VERSION ""

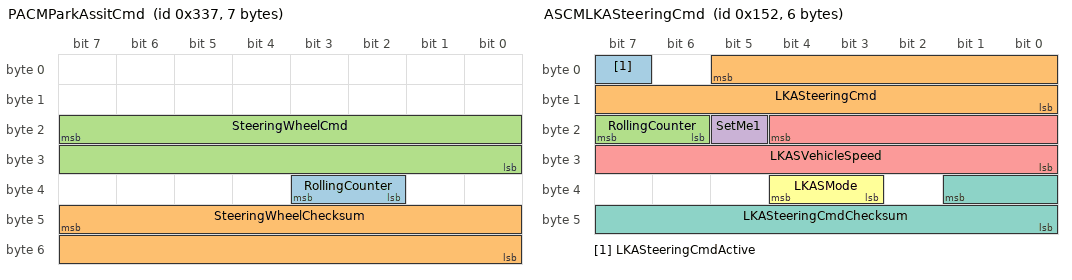
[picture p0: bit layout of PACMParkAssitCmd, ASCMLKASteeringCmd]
BO_ 823 PACMParkAssitCmd: 7 NEO
 SG_ RollingCounter : 35|2@0+ (1,0) [0|0] ""  NEO
 SG_ SteeringWheelChecksum : 47|16@0+ (1,0) [0|0] ""  NEO
 SG_ SteeringWheelCmd : 23|16@0+ (1,0) [0|0] ""  NEO

BO_ 560 EBCMRegen: 6 K17_EBCM
 SG_ Regen : 1|10@0+ (1,0) [0|0] ""  NEO

BO_ 338 ASCMLKASteeringCmd: 6 NEO
 SG_ LKASteeringCmdActive : 7|1@0+ (1,0) [0|0] ""  NEO
 SG_ LKASteeringCmd : 5|14@0- (1,0) [0|0] ""  NEO
 SG_ RollingCounter : 23|2@0+ (1,0) [0|0] ""  NEO
 SG_ SetMe1 : 21|1@0+ (1,0) [0|0] ""  NEO
 SG_ LKASVehicleSpeed : 20|13@0+ (0.22,0) [0|0] "kph" NEO
 SG_ LKASMode : 36|2@0+ (1,0) [0|0] ""  NEO
 SG_ LKASteeringCmdChecksum : 33|10@0+ (1,0) [0|0] ""  NEO

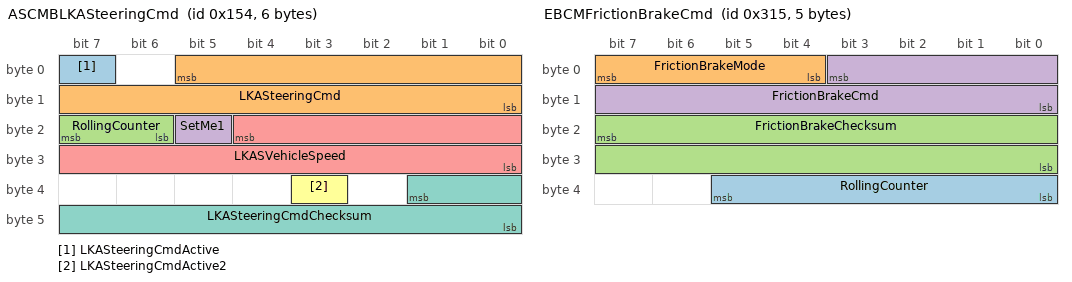
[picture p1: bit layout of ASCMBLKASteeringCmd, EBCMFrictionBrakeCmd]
BO_ 340 ASCMBLKASteeringCmd: 6 NEO
 SG_ LKASteeringCmdActive : 7|1@0+ (1,0) [0|0] ""  NEO
 SG_ LKASteeringCmd : 5|14@0- (1,0) [0|0] ""  NEO
 SG_ RollingCounter : 23|2@0+ (1,0) [0|0] ""  NEO
 SG_ SetMe1 : 21|1@0+ (1,0) [0|0] ""  NEO
 SG_ LKASVehicleSpeed : 20|13@0+ (0.22,0) [0|0] "kph" NEO
 SG_ LKASteeringCmdActive2 : 35|1@0+ (1,0) [0|0] ""  NEO
 SG_ LKASteeringCmdChecksum : 33|10@0+ (1,0) [0|0] ""  NEO

BO_ 368 EBCMFrictionBrakeStatus: 8 K17_EBCM
 SG_ FrictionBrakePressure : 23|16@0+ (1,0) [0|0] ""  NEO

BO_ 789 EBCMFrictionBrakeCmd: 5 K17_EBCM
 SG_ RollingCounter : 37|6@0+ (1,0) [0|0] ""  NEO
 SG_ FrictionBrakeMode : 7|4@0+ (1,0) [0|0] ""  NEO
 SG_ FrictionBrakeChecksum : 23|16@0+ (1,0) [0|0] ""  NEO
 SG_ FrictionBrakeCmd : 3|12@0- (1,0) [0|0] ""  NEO

BO_TX_BU_ 823 : K43_PSCM,NEO;
BO_TX_BU_ 789 : NEO,K17_EBCM;

BU_: K16_BECM K73_TCIC K9_BCM K43_PSCM K17_EBCM K20_ECM K114B_HPCM NEO K124_ASCM
VAL_TABLE_ TurnSignals 2 "Right Turn" 1 "Left Turn" 0 "None" ;
VAL_TABLE_ ACCLeadCar 1 "Present" 0 "Not Present" ;
VAL_TABLE_ ACCCmdActive 1 "Active" 0 "Inactive" ;
VAL_TABLE_ BrakePedalPressed 1 "Pressed" 0 "Depressed" ;
VAL_TABLE_ DistanceButton 1 "Active" 0 "Inactive" ;
VAL_TABLE_ LKAButton 1 "Active" 0 "Inactive" ;
VAL_TABLE_ ACCButtons 6 "Cancel" 5 "Main" 3 "Set" 2 "Resume" 1 "None" ;
VAL_TABLE_ PRNDL 3 "Reverse" 2 "Drive" 1 "Neutral" 0 "Park" ;
VAL_TABLE_ DoorStatus 1 "Opened" 0 "Closed" ;
VAL_TABLE_ SeatBeltStatus 1 "Latched" 0 "Unlatched" ;
VAL_TABLE_ LKASteeringCmdActive 1 "Active" 0 "Inactive" ;
VAL_TABLE_ ACCGapLevel 3 "Far" 2 "Med" 1 "Near" 0 "Inactive" ;
VAL_TABLE_ GasRegenCmdActiveInv 1 "Inactive" 0 "Active" ;
VAL_TABLE_ GasRegenCmdActive 1 "Active" 0 "Inactive" ;
VAL_TABLE_ LKATorqueDeliveredStatus 3 "Failed" 2 "Temp. Limited" 1 "Active" 0 "Inactive" ;
VAL_TABLE_ HandsOffSWDetectionStatus 1 "Hands On" 0 "Hands Off" ;
VAL_TABLE_ HandsOffSWDetectionMode 2 "Failed" 1 "Enabled" 0 "Disabled" ;

CM_ "BO_ E_EMS11: All (plug-in) hybrids use this gas signal: CR_Vcu_AccPedDep_Pos, and all EVs use the Accel_Pedal_Pos signal. See hyundai/values.py for a specific car list";
CM_ SG_ 871 CF_Lvr_IsgState "Idle Stop and Go";
CM_ SG_ 1056 SCCInfoDisplay "Goes to 1 for a second while transitioning from Cruise Control to No Message";
CM_ SG_ 1348 SpeedLim_Nav_Clu "Speed limit displayed on Nav, Cluster and HUD";
